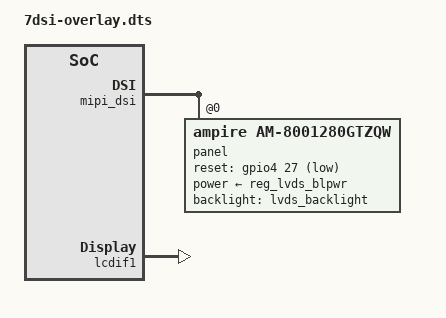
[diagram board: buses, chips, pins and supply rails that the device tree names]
// SPDX-License-Identifier: (GPL-2.0+ OR MIT)
/*
 * Copyright 2023 ADLINK Technology Corp.
 *
 * Author: Po Cheng <po.cheng@adlinktech.com>
 */

/dts-v1/;
/plugin/;

/ {
	fragment@0 {
		target-path = "/";
		__overlay__ {
			lvds_backlight {
				status = "okay";
			};
		};
	};

	fragment@1 {
		target = <&mipi_dsi>;
		__overlay__ {
			#address-cells = <1>;
			#size-cells = <0>;
			status = "okay";
			panel@0 {
				compatible = "ampire,am-8001280gtzqw", "ilitek,ili9881c";
				reg = <0>;
				power-supply = <&reg_lvds_blpwr>;
				reset-gpios = <&gpio4 27 1>; /* GPIO_ACTIVE_LOW */
				backlight = <&lvds_backlight>;
				flip-horizontal;
				flip-vertical;
				status = "okay";
			};
		};
	};

	fragment@2 {
		target = <&lcdif1>;
		__overlay__ {
			status = "okay";
		};
	};
};

